AUTOSAR XML (schema 00054)
package /SwComponentTypes
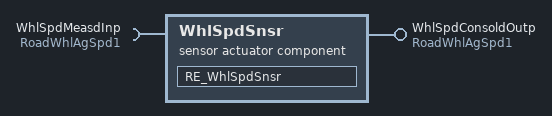
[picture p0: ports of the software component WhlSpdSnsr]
  sensor actuator sw component type WhlSpdSnsr: sensor-actuator=SensorActuatorType
    provide port WhlSpdConsoldOutp: provided-interface=RoadWhlAgSpd1
    require port WhlSpdMeasdInp: nonqueued-receiver-com-spec{data-element=RoadWhlAgSpd, init-value=Default_WhlSpdMeasdInp:0}, required-interface=RoadWhlAgSpd1
    behavior WhlSpdSnsr_IB: data-type-mapping=DataTypeMappingSet_AgSpd, supports-multiple-instantiation=true
      data received event DRE_WhlSpdMeasdInp: start-on-event=RE_WhlSpdSnsr, data=WhlSpdMeasdInp.RoadWhlAgSpd
      runnable RE_WhlSpdSnsr: minimum-start-interval=0.01
        data-read-access:
          access DRA_WhlSpdMeasdInp: accessed-variable=WhlSpdMeasdInp.RoadWhlAgSpd
        data-send-points:
          access DSP_WhlSpdConsoldOutp: accessed-variable=WhlSpdConsoldOutp.RoadWhlAgSpd
